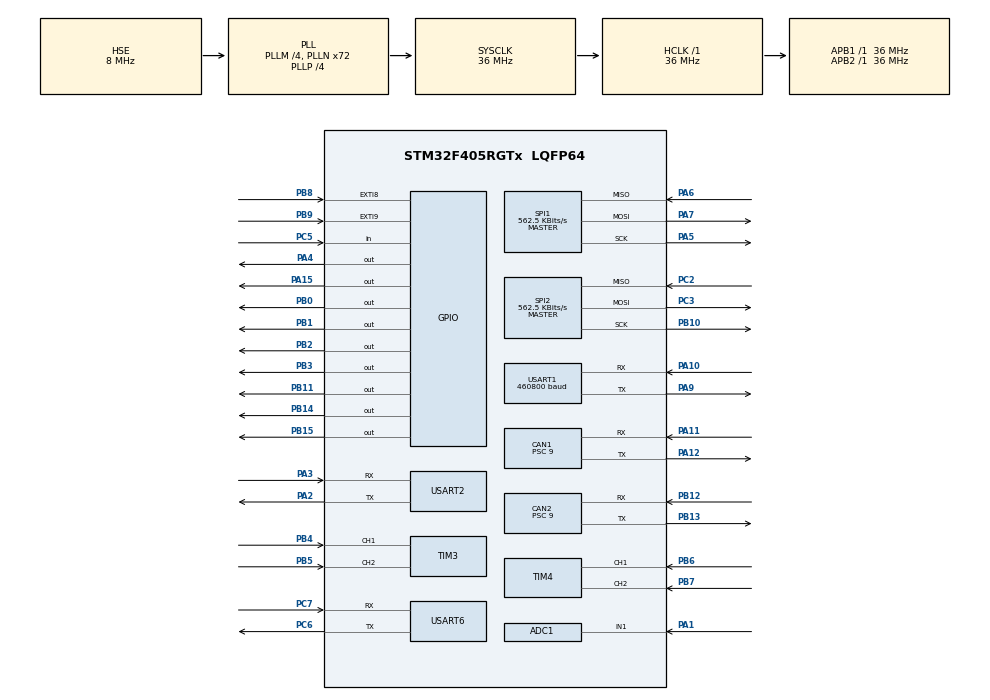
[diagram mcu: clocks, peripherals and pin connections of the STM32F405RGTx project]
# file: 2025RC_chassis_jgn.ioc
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ADC1.Channel-0\#ChannelRegularConversion=ADC_CHANNEL_1
ADC1.DMAContinuousRequests=DISABLE
ADC1.ExternalTrigConv=ADC_EXTERNALTRIGCONV_T2_TRGO
ADC1.NbrOfConversion=1
ADC1.NbrOfConversionFlag=1
ADC1.Rank-0\#ChannelRegularConversion=1
ADC1.SamplingTime-0\#ChannelRegularConversion=ADC_SAMPLETIME_56CYCLES
ADC1.ScanConvMode=DISABLE
ADC1.master=1
CAN1.BS1=CAN_BS1_2TQ
CAN1.BS2=CAN_BS2_1TQ
CAN1.CalculateBaudRate=1000000
CAN1.CalculateTimeBit=1000
CAN1.CalculateTimeQuantum=250.0
CAN1.Mode=CAN_MODE_NORMAL
CAN1.NART=ENABLE
CAN1.Prescaler=9
CAN2.ABOM=ENABLE
CAN2.BS1=CAN_BS1_2TQ
CAN2.CalculateBaudRate=1000000
CAN2.CalculateTimeBit=1000
CAN2.CalculateTimeQuantum=250.0
CAN2.NART=ENABLE
CAN2.Prescaler=9
FREERTOS.Tasks01=defaultTask,24,128,StartDefaultTask,Default,NULL,Dynamic,NULL,NULL;LocateTask,40,512,TaskLocate,As external,NULL,Dynamic,NULL,NULL;ChassisTask,24,512,TaskChassis,As external,NULL,Dynamic,NULL,NULL;MonitorTask,8,512,TaskMonitor,As external,NULL,Dynamic,NULL,NULL
FREERTOS.configTOTAL_HEAP_SIZE=10000
Mcu.Family=STM32F4
Mcu.Name=STM32F405RGTx
Mcu.Package=LQFP64
NVIC.ADC_IRQn=true\:3\:0\:true\:false\:true\:false\:true\:true\:true
NVIC.CAN1_RX0_IRQn=true\:0\:0\:true\:false\:true\:false\:true\:true\:true
NVIC.CAN2_RX1_IRQn=true\:0\:0\:true\:false\:true\:false\:true\:true\:true
NVIC.EXTI9_5_IRQn=true\:4\:0\:true\:false\:true\:false\:true\:true\:true
NVIC.PriorityGroup=NVIC_PRIORITYGROUP_4
NVIC.TIM1_UP_TIM10_IRQn=true\:2\:0\:true\:false\:true\:false\:true\:true\:true
NVIC.TIM5_IRQn=true\:2\:0\:true\:false\:true\:false\:true\:true\:true
NVIC.TIM7_IRQn=true\:15\:0\:false\:false\:true\:false\:false\:true\:true
NVIC.TimeBase=TIM7_IRQn
NVIC.TimeBaseIP=TIM7
NVIC.USART1_IRQn=true\:1\:0\:true\:false\:true\:false\:true\:true\:true
NVIC.USART2_IRQn=true\:1\:0\:true\:false\:true\:false\:true\:true\:true
NVIC.USART6_IRQn=true\:0\:0\:true\:false\:true\:false\:true\:true\:true
PA1.Signal=ADCx_IN1
PA10.GPIO_PuPd=GPIO_PULLUP
PA10.Mode=Asynchronous
PA10.Signal=USART1_RX
PA11.Mode=CAN_Activate
PA11.Signal=CAN1_RX
PA12.Mode=CAN_Activate
PA12.Signal=CAN1_TX
PA13.Mode=Serial_Wire
PA13.Signal=SYS_JTMS-SWDIO
PA14.Mode=Serial_Wire
PA14.Signal=SYS_JTCK-SWCLK
PA15.Signal=GPIO_Output
PA2.GPIO_PuPd=GPIO_PULLUP
PA2.Mode=Asynchronous
PA2.Signal=USART2_TX
PA3.GPIO_PuPd=GPIO_PULLUP
PA3.Mode=Asynchronous
PA3.Signal=USART2_RX
PA4.GPIO_PuPd=GPIO_PULLUP
PA4.GPIO_Speed=GPIO_SPEED_FREQ_VERY_HIGH
PA4.PinState=GPIO_PIN_SET
PA4.Signal=GPIO_Output
PA5.Mode=Full_Duplex_Master
PA5.Signal=SPI1_SCK
PA6.Mode=Full_Duplex_Master
PA6.Signal=SPI1_MISO
PA7.Mode=Full_Duplex_Master
PA7.Signal=SPI1_MOSI
PA9.GPIO_PuPd=GPIO_PULLUP
PA9.Mode=Asynchronous
PA9.Signal=USART1_TX
PB0.Signal=GPIO_Output
PB1.Signal=GPIO_Output
PB10.Mode=Full_Duplex_Master
PB10.Signal=SPI2_SCK
PB11.GPIO_PuPd=GPIO_PULLUP
PB11.Signal=GPIO_Output
PB12.Mode=CAN_Activate
PB12.Signal=CAN2_RX
PB13.Mode=CAN_Activate
PB13.Signal=CAN2_TX
PB14.Signal=GPIO_Output
PB15.Signal=GPIO_Output
PB2.Signal=GPIO_Output
PB3.GPIO_PuPd=GPIO_PULLUP
PB3.Signal=GPIO_Output
PB4.Signal=S_TIM3_CH1
PB5.Signal=S_TIM3_CH2
PB6.Signal=S_TIM4_CH1
PB7.Signal=S_TIM4_CH2
PB8.GPIO_ModeDefaultEXTI=GPIO_MODE_IT_RISING
PB8.GPIO_PuPd=GPIO_PULLDOWN
PB8.Signal=GPXTI8
PB9.GPIO_ModeDefaultEXTI=GPIO_MODE_IT_RISING
PB9.GPIO_PuPd=GPIO_PULLDOWN
PB9.Signal=GPXTI9
PC2.Mode=Full_Duplex_Master
PC2.Signal=SPI2_MISO
PC3.Mode=Full_Duplex_Master
PC3.Signal=SPI2_MOSI
PC5.GPIO_PuPd=GPIO_PULLUP
PC5.Signal=GPIO_Input
PC6.GPIO_PuPd=GPIO_PULLUP
PC6.Mode=Asynchronous
PC6.Signal=USART6_TX
PC7.GPIO_PuPd=GPIO_PULLUP
PC7.Mode=Asynchronous
PC7.Signal=USART6_RX
PH0-OSC_IN.Mode=HSE-External-Oscillator
PH0-OSC_IN.Signal=RCC_OSC_IN
PH1-OSC_OUT.Mode=HSE-External-Oscillator
PH1-OSC_OUT.Signal=RCC_OSC_OUT
ProjectManager.HeapSize=0x200
ProjectManager.StackSize=0x400
ProjectManager.TargetToolchain=MDK-ARM V5.27
RCC.48MHZClocksFreq_Value=36000000
RCC.AHBFreq_Value=36000000
RCC.APB1Freq_Value=36000000
RCC.APB1TimFreq_Value=36000000
RCC.APB2Freq_Value=36000000
RCC.APB2TimFreq_Value=36000000
RCC.CortexFreq_Value=36000000
RCC.HCLKFreq_Value=36000000
RCC.HSE_VALUE=8000000
RCC.HSI_VALUE=16000000
RCC.LSE_VALUE=32768
RCC.PLLM=4
RCC.PLLN=72
RCC.PLLP=RCC_PLLP_DIV4
RCC.PLLSourceVirtual=RCC_PLLSOURCE_HSE
RCC.SYSCLKFreq_VALUE=36000000
RCC.SYSCLKSource=RCC_SYSCLKSOURCE_PLLCLK
RCC.VCOOutputFreq_Value=144000000
SH.ADCx_IN1.0=ADC1_IN1,IN1
SH.S_TIM3_CH1.0=TIM3_CH1,Encoder_Interface
SH.S_TIM3_CH2.0=TIM3_CH2,Encoder_Interface
SH.S_TIM4_CH1.0=TIM4_CH1,Encoder_Interface
SH.S_TIM4_CH2.0=TIM4_CH2,Encoder_Interface
SPI1.BaudRatePrescaler=SPI_BAUDRATEPRESCALER_64
SPI1.CLKPhase=SPI_PHASE_2EDGE
SPI1.CRCCalculation=SPI_CRCCALCULATION_DISABLE
SPI1.CalculateBaudRate=562.5 KBits/s
SPI1.DataSize=SPI_DATASIZE_8BIT
SPI1.Direction=SPI_DIRECTION_2LINES
SPI1.Mode=SPI_MODE_MASTER
SPI1.VirtualType=VM_MASTER
SPI2.BaudRatePrescaler=SPI_BAUDRATEPRESCALER_64
SPI2.CLKPhase=SPI_PHASE_2EDGE
SPI2.CalculateBaudRate=562.5 KBits/s
SPI2.DataSize=SPI_DATASIZE_8BIT
SPI2.Direction=SPI_DIRECTION_2LINES
SPI2.Mode=SPI_MODE_MASTER
SPI2.VirtualType=VM_MASTER
STMicroelectronics.X-CUBE-ALGOBUILD.1.3.0.LibraryCcDSPOoLibraryJjDSPOoLibrary=true
TIM10.Period=10000
TIM10.Prescaler=35
TIM2.Period=99
TIM2.Prescaler=35
TIM2.TIM_MasterOutputTrigger=TIM_TRGO_UPDATE
TIM3.EncoderMode=TIM_ENCODERMODE_TI12
TIM4.EncoderMode=TIM_ENCODERMODE_TI12
TIM5.Period=1999
TIM5.Prescaler=35
TIM6.Prescaler=35
USART1.BaudRate=460800
USART1.OverSampling=UART_OVERSAMPLING_8
USART1.VirtualMode=VM_ASYNC
USART2.OverSampling=UART_OVERSAMPLING_8
USART2.VirtualMode=VM_ASYNC
USART6.OverSampling=UART_OVERSAMPLING_8
USART6.VirtualMode=VM_ASYNC
VP_FREERTOS_VS_CMSIS_V2.Mode=CMSIS_V2
VP_STMicroelectronics.X-CUBE-ALGOBUILD_VS_DSPOoLibraryJjLibrary_1.3.0_1.3.0.Mode=DSPOoLibraryJjLibrary
VP_SYS_VS_tim7.Mode=TIM7
VP_TIM10_VS_ClockSourceINT.Mode=Enable_Timer
VP_TIM2_VS_ClockSourceINT.Mode=Internal
VP_TIM5_VS_ClockSourceINT.Mode=Internal
VP_TIM6_VS_ClockSourceINT.Mode=Enable_Timer
board=custom

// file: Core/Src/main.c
/* USER CODE BEGIN Header */
/**
  ******************************************************************************
  * @file           : main.c
  * @brief          : Main program body
  ******************************************************************************
  * @attention
  *
  * Copyright (c) 2024 STMicroelectronics.
  * All rights reserved.
  *
  * This software is licensed under terms that can be found in the LICENSE file
  * in the root directory of this software component.
  * If no LICENSE file comes with this software, it is provided AS-IS.
  *
  ******************************************************************************
  */
/* USER CODE END Header */
#include "main.h"
#include "cmsis_os.h"
#include "adc.h"
#include "can.h"
#include "spi.h"
#include "tim.h"
#include "usart.h"
#include "gpio.h"

/* USER CODE BEGIN Includes */
#include "locate.h"
#include "CAN_basic.h"
/* USER CODE END Includes */

void SystemClock_Config(void);
void MX_FREERTOS_Init(void);

int main(void)
{

  /* MCU Configuration--------------------------------------------------------*/

  /* Reset of all peripherals, Initializes the Flash interface and the Systick. */
  HAL_Init();

  /* Configure the system clock */
  SystemClock_Config();

  /* Initialize all configured peripherals */
  MX_GPIO_Init();
  MX_CAN1_Init();
  MX_SPI2_Init();
  MX_CAN2_Init();
  MX_USART1_UART_Init();
  MX_SPI1_Init();
  MX_USART2_UART_Init();
  MX_USART6_UART_Init();
  MX_TIM6_Init();
  MX_TIM3_Init();
  MX_TIM4_Init();
  MX_TIM5_Init();
  MX_ADC1_Init();
  MX_TIM2_Init();
  MX_TIM10_Init();
  /* USER CODE BEGIN 2 */
	HAL_TIM_Base_Start_IT(&htim6);
	HAL_TIM_Base_Start_IT(&htim2);
  HAL_TIM_Base_Start_IT(&htim3);
	HAL_TIM_Base_Start_IT(&htim4);

	HAL_UART_Receive_IT(&huart6,&data_uart_rec,1);
	HAL_ADC_Start_IT(&hadc1);
	CAN1_Start();
	CAN2_Start();
  /* USER CODE END 2 */

  /* Init scheduler */
  osKernelInitialize();  /* Call init function for freertos objects (in freertos.c) */
  MX_FREERTOS_Init();

  /* Start scheduler */
  osKernelStart();

  /* We should never get here as control is now taken by the scheduler */
  /* Infinite loop */
  while (1)
  {

  }
}

void SystemClock_Config(void)
{
  RCC_OscInitTypeDef RCC_OscInitStruct = {0};
  RCC_ClkInitTypeDef RCC_ClkInitStruct = {0};

  /** Configure the main internal regulator output voltage
  */
  __HAL_RCC_PWR_CLK_ENABLE();
  __HAL_PWR_VOLTAGESCALING_CONFIG(PWR_REGULATOR_VOLTAGE_SCALE1);

  /** Initializes the RCC Oscillators according to the specified parameters
  * in the RCC_OscInitTypeDef structure.
  */
  RCC_OscInitStruct.OscillatorType = RCC_OSCILLATORTYPE_HSE;
  RCC_OscInitStruct.HSEState = RCC_HSE_ON;
  RCC_OscInitStruct.PLL.PLLState = RCC_PLL_ON;
  RCC_OscInitStruct.PLL.PLLSource = RCC_PLLSOURCE_HSE;
  RCC_OscInitStruct.PLL.PLLM = 4;
  RCC_OscInitStruct.PLL.PLLN = 72;
  RCC_OscInitStruct.PLL.PLLP = RCC_PLLP_DIV4;
  RCC_OscInitStruct.PLL.PLLQ = 4;
  if (HAL_RCC_OscConfig(&RCC_OscInitStruct) != HAL_OK)
  {
    Error_Handler();
  }

  /** Initializes the CPU, AHB and APB buses clocks
  */
  RCC_ClkInitStruct.ClockType = RCC_CLOCKTYPE_HCLK|RCC_CLOCKTYPE_SYSCLK
                              |RCC_CLOCKTYPE_PCLK1|RCC_CLOCKTYPE_PCLK2;
  RCC_ClkInitStruct.SYSCLKSource = RCC_SYSCLKSOURCE_PLLCLK;
  RCC_ClkInitStruct.AHBCLKDivider = RCC_SYSCLK_DIV1;
  RCC_ClkInitStruct.APB1CLKDivider = RCC_HCLK_DIV1;
  RCC_ClkInitStruct.APB2CLKDivider = RCC_HCLK_DIV1;

  if (HAL_RCC_ClockConfig(&RCC_ClkInitStruct, FLASH_LATENCY_1) != HAL_OK)
  {
    Error_Handler();
  }
}

void HAL_TIM_PeriodElapsedCallback(TIM_HandleTypeDef *htim)
{
  /* USER CODE BEGIN Callback 0 */

	if(htim==&htim5)
	{
		UpdateLocateInfo(&g_Chassis_Instance);
	}
  /* USER CODE END Callback 0 */
  if (htim->Instance == TIM7) {
    HAL_IncTick();
  }
}

void Error_Handler(void)
{
  __disable_irq();
  while (1)
  {
  }
}

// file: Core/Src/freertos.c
/* USER CODE BEGIN Header */
/**
  ******************************************************************************
  * File Name          : freertos.c
  * Description        : Code for freertos applications
  ******************************************************************************
  * @attention
  *
  * Copyright (c) 2024 STMicroelectronics.
  * All rights reserved.
  *
  * This software is licensed under terms that can be found in the LICENSE file
  * in the root directory of this software component.
  * If no LICENSE file comes with this software, it is provided AS-IS.
  *
  ******************************************************************************
  */
/* USER CODE END Header */

#include "FreeRTOS.h"
#include "task.h"
#include "main.h"
#include "cmsis_os.h"

/* Definitions for defaultTask */
osThreadId_t defaultTaskHandle;
const osThreadAttr_t defaultTask_attributes = {
  .name = "defaultTask",
  .stack_size = 128 * 4,
  .priority = (osPriority_t) osPriorityNormal,
};
/* Definitions for LocateTask */
osThreadId_t LocateTaskHandle;
const osThreadAttr_t LocateTask_attributes = {
  .name = "LocateTask",
  .stack_size = 512 * 4,
  .priority = (osPriority_t) osPriorityHigh,
};
/* Definitions for ChassisTask */
osThreadId_t ChassisTaskHandle;
const osThreadAttr_t ChassisTask_attributes = {
  .name = "ChassisTask",
  .stack_size = 512 * 4,
  .priority = (osPriority_t) osPriorityNormal,
};
/* Definitions for MonitorTask */
osThreadId_t MonitorTaskHandle;
const osThreadAttr_t MonitorTask_attributes = {
  .name = "MonitorTask",
  .stack_size = 512 * 4,
  .priority = (osPriority_t) osPriorityLow,
};

void StartDefaultTask(void *argument);
extern void TaskLocate(void *argument);
extern void TaskChassis(void *argument);
extern void TaskMonitor(void *argument);

void MX_FREERTOS_Init(void); /* (MISRA C 2004 rule 8.1) */

void MX_FREERTOS_Init(void) {

  /* Create the thread(s) */
  /* creation of defaultTask */
  defaultTaskHandle = osThreadNew(StartDefaultTask, NULL, &defaultTask_attributes);

  /* creation of LocateTask */
  LocateTaskHandle = osThreadNew(TaskLocate, NULL, &LocateTask_attributes);

  /* creation of ChassisTask */
  ChassisTaskHandle = osThreadNew(TaskChassis, NULL, &ChassisTask_attributes);

  /* creation of MonitorTask */
  MonitorTaskHandle = osThreadNew(TaskMonitor, NULL, &MonitorTask_attributes);

}

void StartDefaultTask(void *argument)
{
  for(;;)
  {
    osDelay(1);
  }
}
